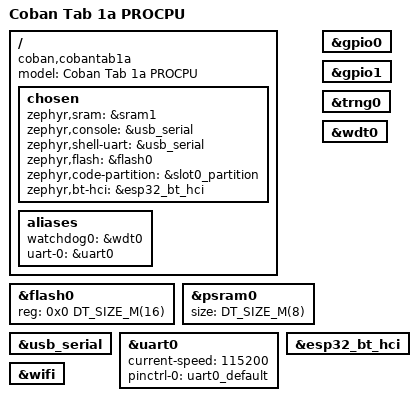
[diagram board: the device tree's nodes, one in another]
/*
 * Copyright (c) 2026 The ZMK Contributors
 *
 * SPDX-License-Identifier: MIT
 */

/dts-v1/;

#include <espressif/esp32s3/esp32s3.dtsi>
#include "cobantab1a_esp32s3_procpu-pinctrl.dtsi"
#include <espressif/partitions_0x0_default_16M.dtsi>

/*
 * Coban Tab 1a (PROCPU only): ESP32-S3-WROOM-1 N16R8, 16 MB flash + 8 MB octal
 * PSRAM. USB-C is on the internal PHY in Serial/JTAG mode (no external PHY) for
 * console, flashing and recovery, with UART0 (GPIO43/44) as the backup console.
 * The AXS15231B QSPI display, its I2C touch and the PWM backlight are described
 * by the cobantab1a shield in the config repo, not here.
 */

/*
 * Geometry the removed Zephyr 4.5 per-module dtsi (esp32s3_wroom_n16r8.dtsi)
 * used to provide; boards must now state it themselves.
 */
&flash0 {
    reg = <0x0 DT_SIZE_M(16)>;
};

&psram0 {
    size = <DT_SIZE_M(8)>;
};

/ {
    model = "Coban Tab 1a PROCPU";
    compatible = "coban,cobantab1a";

    chosen {
        zephyr,sram = &sram1;
        zephyr,console = &usb_serial;
        zephyr,shell-uart = &usb_serial;
        zephyr,flash = &flash0;
        zephyr,code-partition = &slot0_partition;
        zephyr,bt-hci = &esp32_bt_hci;
    };

    aliases {
        watchdog0 = &wdt0;
        uart-0 = &uart0;
    };
};

&usb_serial {
    status = "okay";
};

&uart0 {
    status = "okay";
    current-speed = <115200>;
    pinctrl-0 = <&uart0_default>;
    pinctrl-names = "default";
};

&gpio0 {
    status = "okay";
};

&gpio1 {
    status = "okay";
};

&trng0 {
    status = "okay";
};

&wdt0 {
    status = "okay";
};

&esp32_bt_hci {
    status = "okay";
};

&wifi {
    status = "okay";
};
